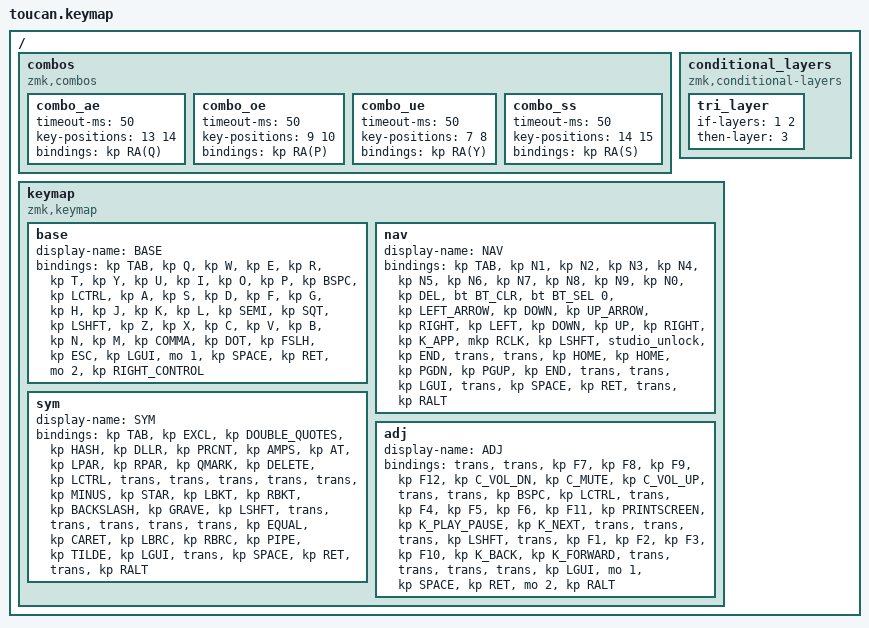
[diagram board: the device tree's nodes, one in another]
#include <dt-bindings/zmk/mouse.h> // Wichtig für Rechtsklick!
#include <behaviors.dtsi>
#include <dt-bindings/zmk/bt.h>
#include <dt-bindings/zmk/keys.h>
#include <dt-bindings/zmk/pointing.h>

#define BASE 0
#define NAV  1
#define SYM  2
#define ADJ  3

/ {
    // Combos: Drücke zwei Tasten gleichzeitig für deutsche Buchstaben
    // Funktioniert am besten, wenn dein Fedora auf "English (US, intl., with dead keys)" steht

    combos {
        compatible = "zmk,combos";

        combo_ae {
            timeout-ms = <50>;
            key-positions = <13 14>;
            bindings = <&kp RA(Q)>;
        }; // A+S = ä
        combo_oe {
            timeout-ms = <50>;
            key-positions = <9 10>;
            bindings = <&kp RA(P)>;
        }; // O+P = ö
        combo_ue {
            timeout-ms = <50>;
            key-positions = <7 8>;
            bindings = <&kp RA(Y)>;
        }; // U+I = ü
        combo_ss {
            timeout-ms = <50>;
            key-positions = <14 15>;
            bindings = <&kp RA(S)>;
        }; // S+D = ß
    };

    conditional_layers {
        compatible = "zmk,conditional-layers";

        tri_layer {
            if-layers = <1 2>;
            then-layer = <3>;
        };
    };

    keymap {
        compatible = "zmk,keymap";

        base {
            display-name = "BASE";
            bindings = <
&kp TAB  &kp Q  &kp W  &kp E  &kp R  &kp T  &kp Y  &kp U  &kp I  &kp O  &kp P  &kp BSPC  &kp LCTRL  &kp A  &kp S  &kp D  &kp F  &kp G  &kp H  &kp J  &kp K  &kp L  &kp SEMI  &kp SQT  &kp LSHFT  &kp Z  &kp X  &kp C  &kp V  &kp B  &kp N  &kp M  &kp COMMA  &kp DOT  &kp FSLH  &kp ESC  &kp LGUI  &mo 1  &kp SPACE  &kp RET  &mo 2  &kp RIGHT_CONTROL
            >;
        };

        nav {
            display-name = "NAV";
            bindings = <
&kp TAB  &kp N1  &kp N2  &kp N3  &kp N4  &kp N5  &kp N6  &kp N7  &kp N8  &kp N9  &kp N0  &kp DEL  &bt BT_CLR  &bt BT_SEL 0  &kp LEFT_ARROW  &kp DOWN  &kp UP_ARROW  &kp RIGHT  &kp LEFT  &kp DOWN  &kp UP  &kp RIGHT  &kp K_APP  &mkp RCLK  &kp LSHFT  &studio_unlock  &kp END  &trans  &trans  &kp HOME  &kp HOME  &kp PGDN  &kp PGUP  &kp END  &trans  &trans  &kp LGUI  &trans  &kp SPACE  &kp RET  &trans  &kp RALT
            >;
        };

        sym {
            display-name = "SYM";
            bindings = <
&kp TAB  &kp EXCL  &kp DOUBLE_QUOTES  &kp HASH  &kp DLLR  &kp PRCNT  &kp AMPS  &kp AT  &kp LPAR  &kp RPAR  &kp QMARK  &kp DELETE  &kp LCTRL  &trans  &trans  &trans  &trans  &trans  &kp MINUS  &kp STAR  &kp LBKT  &kp RBKT  &kp BACKSLASH  &kp GRAVE  &kp LSHFT  &trans  &trans  &trans  &trans  &trans  &kp EQUAL  &kp CARET  &kp LBRC  &kp RBRC  &kp PIPE  &kp TILDE  &kp LGUI  &trans  &kp SPACE  &kp RET  &trans  &kp RALT
            >;
        };

        adj {
            display-name = "ADJ";
            bindings = <
&trans  &trans  &kp F7  &kp F8  &kp F9  &kp F12  &kp C_VOL_DN  &kp C_MUTE  &kp C_VOL_UP  &trans  &trans  &kp BSPC  &kp LCTRL  &trans  &kp F4  &kp F5  &kp F6  &kp F11  &kp PRINTSCREEN  &kp K_PLAY_PAUSE  &kp K_NEXT  &trans  &trans  &trans  &kp LSHFT  &trans  &kp F1  &kp F2  &kp F3  &kp F10  &kp K_BACK  &kp K_FORWARD  &trans  &trans  &trans  &trans  &kp LGUI  &mo 1  &kp SPACE  &kp RET  &mo 2  &kp RALT
            >;
        };
    };
};
